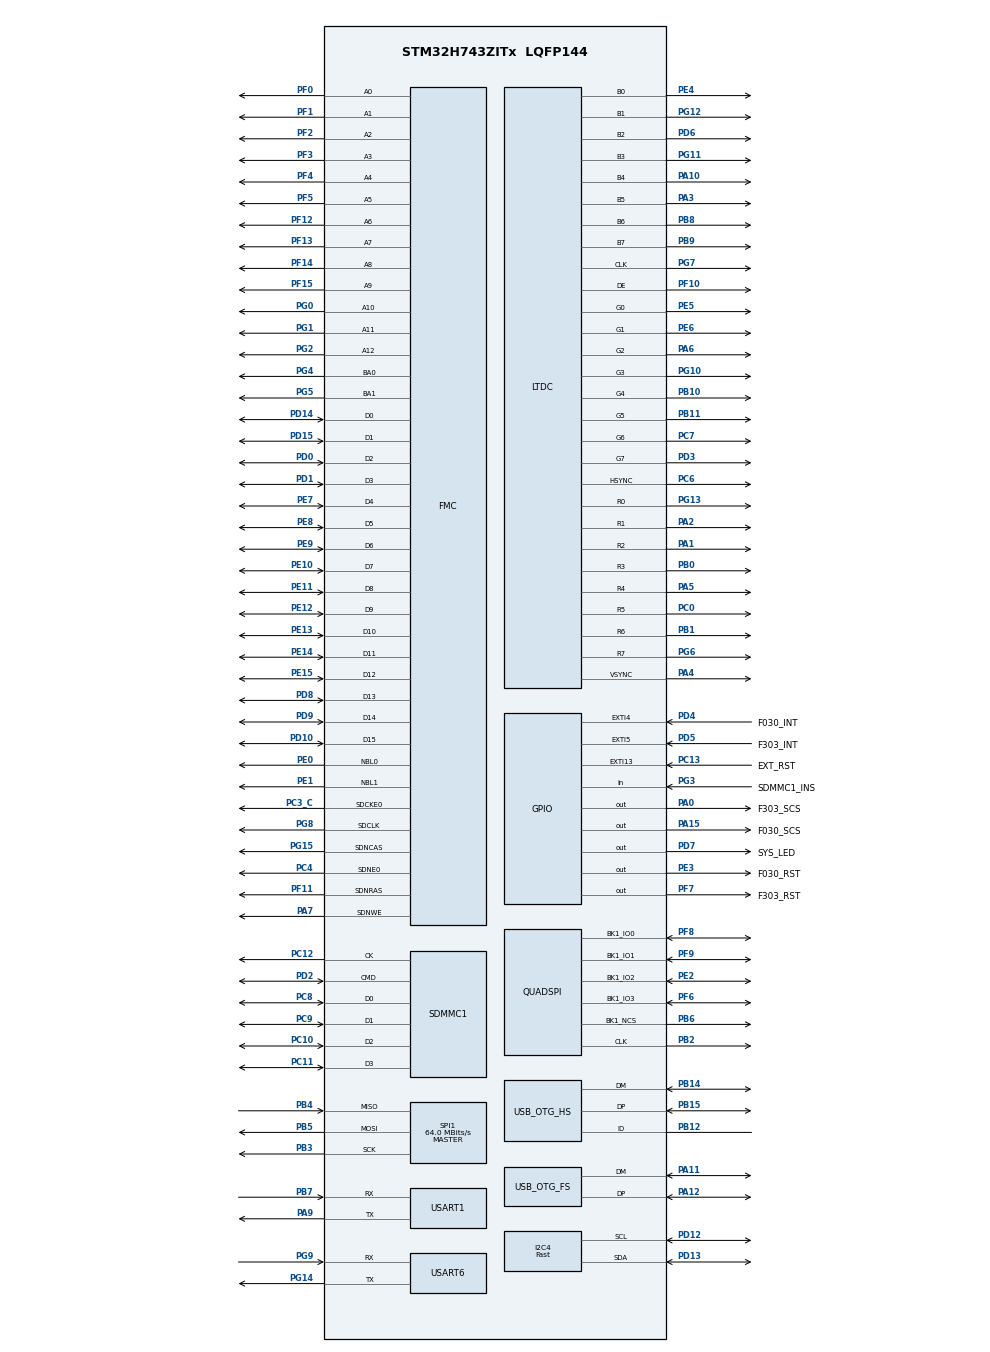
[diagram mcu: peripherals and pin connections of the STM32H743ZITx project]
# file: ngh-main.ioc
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CORTEX_M7.CPU_DCache=Enabled
CORTEX_M7.CPU_ICache=Enabled
CORTEX_M7.MPU_Control=__NULL
DMA2D.ColorMode=DMA2D_OUTPUT_ARGB8888
DMA2D.Mode=DMA2D_R2M
FATFS.BSP.number=1
FATFS.USE_DMA_CODE_SD=1
FATFS._STRF_ENCODE=3
FATFS._USE_LFN=1
FATFS0.BSP.STBoard=false
FATFS0.BSP.api=Unknown
FATFS0.BSP.i2caddr=0
FATFS0.BSP.instance=PG3
FATFS0.BSP.ip=GPIO
FATFS0.BSP.mode=Input
FATFS0.BSP.name=Detect_SDIO
FATFS0.BSP.solution=PG3
FMC.CASLatency1=FMC_SDRAM_CAS_LATENCY_2
FMC.ColumnBitsNumber1=FMC_SDRAM_COLUMN_BITS_NUM_9
FMC.ExitSelfRefreshDelay1=8
FMC.LoadToActiveDelay1=2
FMC.RCDDelay1=2
FMC.RPDelay1=2
FMC.RPDelay2=2
FMC.ReadBurst1=FMC_SDRAM_RBURST_ENABLE
FMC.ReadBurst2=FMC_SDRAM_RBURST_ENABLE
FMC.RowCycleDelay1=6
FMC.RowCycleDelay2=6
FMC.SDClockPeriod1=FMC_SDRAM_CLOCK_PERIOD_2
FMC.SDClockPeriod2=FMC_SDRAM_CLOCK_PERIOD_2
FMC.SelfRefreshTime1=6
FMC.WriteRecoveryTime1=4
I2C4.I2C_Speed_Mode=I2C_Fast
I2C4.Timing=0x009034B6
LTDC.ActiveH=480
LTDC.ActiveW=854
LTDC.Alpha0_L0=255
LTDC.Alpha_L0=255
LTDC.BlendingFactor1_L0=LTDC_BLENDING_FACTOR1_CA
LTDC.BlendingFactor2_L0=LTDC_BLENDING_FACTOR2_CA
LTDC.FBStartAdress_L0=0xC0000000
LTDC.HBP=2
LTDC.HFP=8
LTDC.HSync=2
LTDC.ImageHeight_L0=480
LTDC.ImageWidth_L0=854
LTDC.Layers=0
LTDC.PixelFormat_L0=LTDC_PIXEL_FORMAT_ARGB8888
LTDC.VBP=18
LTDC.VFP=20
LTDC.VSync=2
LTDC.WindowX1_L0=854
LTDC.WindowY1_L0=480
Mcu.Family=STM32H7
Mcu.Name=STM32H743ZITx
Mcu.Package=LQFP144
NVIC.DMA2D_IRQn=true\:2\:0\:true\:false\:true\:true
NVIC.EXTI15_10_IRQn=true\:3\:0\:true\:false\:true\:true
NVIC.LTDC_IRQn=true\:1\:0\:true\:false\:true\:true
NVIC.OTG_FS_IRQn=true\:0\:0\:false\:false\:true\:true
NVIC.PriorityGroup=NVIC_PRIORITYGROUP_4
NVIC.TIM16_IRQn=true\:0\:0\:false\:false\:true\:true
PA0.GPIO_Label=F303_SCS
PA0.GPIO_Speed=GPIO_SPEED_FREQ_VERY_HIGH
PA0.PinState=GPIO_PIN_SET
PA0.Signal=GPIO_Output
PA1.Mode=RGB888
PA1.Signal=LTDC_R2
PA10.Mode=RGB888
PA10.Signal=LTDC_B4
PA11.Mode=Device_Only
PA11.Signal=USB_OTG_FS_DM
PA12.Mode=Device_Only
PA12.Signal=USB_OTG_FS_DP
PA13\ (JTMS/SWDIO).Mode=Serial_Wire
PA13\ (JTMS/SWDIO).Signal=SYS_JTMS-SWDIO
PA14\ (JTCK/SWCLK).Mode=Serial_Wire
PA14\ (JTCK/SWCLK).Signal=SYS_JTCK-SWCLK
PA15\ (JTDI).GPIO_Label=F030_SCS
PA15\ (JTDI).GPIO_Speed=GPIO_SPEED_FREQ_VERY_HIGH
PA15\ (JTDI).PinState=GPIO_PIN_SET
PA15\ (JTDI).Signal=GPIO_Output
PA2.Mode=RGB888
PA2.Signal=LTDC_R1
PA3.Mode=RGB888
PA3.Signal=LTDC_B5
PA4.Mode=RGB888
PA4.Signal=LTDC_VSYNC
PA5.Mode=RGB888
PA5.Signal=LTDC_R4
PA6.Mode=RGB888
PA6.Signal=LTDC_G2
PA7.Signal=FMC_SDNWE
PA9.GPIO_PuPd=GPIO_PULLUP
PA9.GPIO_Speed=GPIO_SPEED_FREQ_LOW
PA9.Mode=Multiprocessor_communication
PA9.Signal=USART1_TX
PB0.Mode=RGB888
PB0.Signal=LTDC_R3
PB1.Mode=RGB888
PB1.Signal=LTDC_R6
PB10.Mode=RGB888
PB10.Signal=LTDC_G4
PB11.Mode=RGB888
PB11.Signal=LTDC_G5
PB12.Mode=OTG/Dual-Role-Device-FS
PB12.Signal=USB_OTG_HS_ID
PB14.Mode=OTG/Dual-Role-Device-FS
PB14.Signal=USB_OTG_HS_DM
PB15.Mode=OTG/Dual-Role-Device-FS
PB15.Signal=USB_OTG_HS_DP
PB2.Mode=Single Bank 1
PB2.Signal=QUADSPI_CLK
PB3\ (JTDO/TRACESWO).Mode=Full_Duplex_Master
PB3\ (JTDO/TRACESWO).Signal=SPI1_SCK
PB4\ (NJTRST).Mode=Full_Duplex_Master
PB4\ (NJTRST).Signal=SPI1_MISO
PB5.Mode=Full_Duplex_Master
PB5.Signal=SPI1_MOSI
PB6.Mode=Single Bank 1
PB6.Signal=QUADSPI_BK1_NCS
PB7.GPIO_FM7=__NULL
PB7.GPIO_PuPd=GPIO_PULLUP
PB7.GPIO_Speed=GPIO_SPEED_FREQ_LOW
PB7.Mode=Multiprocessor_communication
PB7.Signal=USART1_RX
PB8.Mode=RGB888
PB8.Signal=LTDC_B6
PB9.Mode=RGB888
PB9.Signal=LTDC_B7
PC0.Mode=RGB888
PC0.Signal=LTDC_R5
PC10.Mode=SD_4_bits_Wide_bus
PC10.Signal=SDMMC1_D2
PC11.Mode=SD_4_bits_Wide_bus
PC11.Signal=SDMMC1_D3
PC12.Mode=SD_4_bits_Wide_bus
PC12.Signal=SDMMC1_CK
PC13.GPIO_Label=EXT_RST
PC13.GPIO_ModeDefaultEXTI=GPIO_MODE_IT_RISING_FALLING
PC13.GPIO_PuPd=GPIO_PULLUP
PC13.Signal=GPXTI13
PC14-OSC32_IN\ (OSC32_IN).Mode=LSE-External-Oscillator
PC14-OSC32_IN\ (OSC32_IN).Signal=RCC_OSC32_IN
PC15-OSC32_OUT\ (OSC32_OUT).Mode=LSE-External-Oscillator
PC15-OSC32_OUT\ (OSC32_OUT).Signal=RCC_OSC32_OUT
PC3_C.Mode=SdramChipSelect1_1
PC3_C.Signal=FMC_SDCKE0
PC4.Mode=SdramChipSelect1_1
PC4.Signal=FMC_SDNE0
PC6.Mode=RGB888
PC6.Signal=LTDC_HSYNC
PC7.Mode=RGB888
PC7.Signal=LTDC_G6
PC8.Mode=SD_4_bits_Wide_bus
PC8.Signal=SDMMC1_D0
PC9.Mode=SD_4_bits_Wide_bus
PC9.Signal=SDMMC1_D1
PD0.Signal=FMC_D2_DA2
PD1.Signal=FMC_D3_DA3
PD10.Signal=FMC_D15_DA15
PD12.Mode=I2C
PD12.Signal=I2C4_SCL
PD13.Mode=I2C
PD13.Signal=I2C4_SDA
PD14.Signal=FMC_D0_DA0
PD15.Signal=FMC_D1_DA1
PD2.Mode=SD_4_bits_Wide_bus
PD2.Signal=SDMMC1_CMD
PD3.Mode=RGB888
PD3.Signal=LTDC_G7
PD4.GPIO_Label=F030_INT
PD4.Signal=GPXTI4
PD5.GPIO_Label=F303_INT
PD5.Signal=GPXTI5
PD6.Mode=RGB888
PD6.Signal=LTDC_B2
PD7.GPIO_Label=SYS_LED
PD7.GPIO_Speed=GPIO_SPEED_FREQ_VERY_HIGH
PD7.Signal=GPIO_Output
PD8.Signal=FMC_D13_DA13
PD9.Signal=FMC_D14_DA14
PE0.Signal=FMC_NBL0
PE1.Signal=FMC_NBL1
PE10.Signal=FMC_D7_DA7
PE11.Signal=FMC_D8_DA8
PE12.Signal=FMC_D9_DA9
PE13.Signal=FMC_D10_DA10
PE14.Signal=FMC_D11_DA11
PE15.Signal=FMC_D12_DA12
PE2.Mode=Single Bank 1
PE2.Signal=QUADSPI_BK1_IO2
PE3.GPIO_Label=F030_RST
PE3.GPIO_Speed=GPIO_SPEED_FREQ_VERY_HIGH
PE3.PinState=GPIO_PIN_SET
PE3.Signal=GPIO_Output
PE4.Mode=RGB888
PE4.Signal=LTDC_B0
PE5.Mode=RGB888
PE5.Signal=LTDC_G0
PE6.Mode=RGB888
PE6.Signal=LTDC_G1
PE7.Signal=FMC_D4_DA4
PE8.Signal=FMC_D5_DA5
PE9.Signal=FMC_D6_DA6
PF0.Signal=FMC_A0
PF1.Signal=FMC_A1
PF10.Mode=RGB888
PF10.Signal=LTDC_DE
PF11.Signal=FMC_SDNRAS
PF12.Signal=FMC_A6
PF13.Signal=FMC_A7
PF14.Signal=FMC_A8
PF15.Signal=FMC_A9
PF2.Signal=FMC_A2
PF3.Signal=FMC_A3
PF4.Signal=FMC_A4
PF5.Signal=FMC_A5
PF6.Mode=Single Bank 1
PF6.Signal=QUADSPI_BK1_IO3
PF7.GPIO_Label=F303_RST
PF7.GPIO_Speed=GPIO_SPEED_FREQ_VERY_HIGH
PF7.PinState=GPIO_PIN_SET
PF7.Signal=GPIO_Output
PF8.Mode=Single Bank 1
PF8.Signal=QUADSPI_BK1_IO0
PF9.Mode=Single Bank 1
PF9.Signal=QUADSPI_BK1_IO1
PG0.Signal=FMC_A10
PG1.Signal=FMC_A11
PG10.Mode=RGB888
PG10.Signal=LTDC_G3
PG11.Mode=RGB888
PG11.Signal=LTDC_B3
PG12.Mode=RGB888
PG12.Signal=LTDC_B1
PG13.Mode=RGB888
PG13.Signal=LTDC_R0
PG14.Mode=Asynchronous
PG14.Signal=USART6_TX
PG15.Signal=FMC_SDNCAS
PG2.Signal=FMC_A12
PG3.GPIO_Label=SDMMC1_INS
PG3.GPIO_PuPd=GPIO_PULLUP
PG3.Signal=GPIO_Input
PG4.Signal=FMC_A14_BA0
PG5.Signal=FMC_A15_BA1
PG6.Mode=RGB888
PG6.Signal=LTDC_R7
PG7.Mode=RGB888
PG7.Signal=LTDC_CLK
PG8.Signal=FMC_SDCLK
PG9.Mode=Asynchronous
PG9.Signal=USART6_RX
PH0-OSC_IN\ (PH0).Mode=HSE-External-Oscillator
PH0-OSC_IN\ (PH0).Signal=RCC_OSC_IN
PH1-OSC_OUT\ (PH1).Mode=HSE-External-Oscillator
PH1-OSC_OUT\ (PH1).Signal=RCC_OSC_OUT
ProjectManager.HeapSize=0x200
ProjectManager.StackSize=0x400
ProjectManager.TargetToolchain=SW4STM32
QUADSPI.ChipSelectHighTime=QSPI_CS_HIGH_TIME_2_CYCLE
QUADSPI.ClockPrescaler=1
QUADSPI.FifoThreshold=4
QUADSPI.FlashSize=22
QUADSPI.SampleShifting=QSPI_SAMPLE_SHIFTING_HALFCYCLE
RCC.ADCFreq_Value=128000000
RCC.APB1Freq_Value=100000000
RCC.APB2Freq_Value=100000000
RCC.APB3Freq_Value=100000000
RCC.APB4Freq_Value=100000000
RCC.CKPERSourceSelection=RCC_CLKPSOURCE_CSI
RCC.CortexFreq_Value=400000000
RCC.D1PPRE=RCC_APB3_DIV2
RCC.D2PPRE1=RCC_APB1_DIV2
RCC.D2PPRE2=RCC_APB2_DIV2
RCC.D3PPRE=RCC_APB4_DIV2
RCC.DIVM1=4
RCC.DIVM2=4
RCC.DIVM3=4
RCC.DIVN1=400
RCC.DIVN2=128
RCC.DIVN3=96
RCC.DIVQ1=8
RCC.DIVQ3=4
RCC.DIVR3=6
RCC.HCLKFreq_Value=200000000
RCC.HPRE=RCC_HCLK_DIV2
RCC.HSE_VALUE=8000000
RCC.PLL1_VCI_Range-AdvancedSettings=RCC_PLL1VCIRANGE_0
RCC.RCC_MCO1Source=RCC_MCO1SOURCE_PLL1QCLK
RCC.RCC_MCODiv1=RCC_MCODIV_10
RCC.RNGCLockSelection=RCC_RNGCLKSOURCE_PLL
RCC.RTCClockSelection=RCC_RTCCLKSOURCE_LSE
RCC.SDMMC1CLockSelection=RCC_SDMMCCLKSOURCE_PLL2
RCC.SPI123CLockSelection=RCC_SPI123CLKSOURCE_PLL2
RCC.SYSCLKFreq_VALUE=400000000
RCC.SYSCLKSource=RCC_SYSCLKSOURCE_PLLCLK
RCC.USART16CLockSelection=RCC_USART16CLKSOURCE_PLL2
RCC.USBCLockSelection=RCC_USBCLKSOURCE_PLL3
RCC.USBFreq_Value=48000000
SDMMC1.ClockDiv=4
SH.FMC_A0.0=FMC_A0,13b-sda1
SH.FMC_A1.0=FMC_A1,13b-sda1
SH.FMC_A10.0=FMC_A10,13b-sda1
SH.FMC_A11.0=FMC_A11,13b-sda1
SH.FMC_A12.0=FMC_A12,13b-sda1
SH.FMC_A14_BA0.0=FMC_BA0,FourSdramBanks1
SH.FMC_A15_BA1.0=FMC_BA1,FourSdramBanks1
SH.FMC_A2.0=FMC_A2,13b-sda1
SH.FMC_A3.0=FMC_A3,13b-sda1
SH.FMC_A4.0=FMC_A4,13b-sda1
SH.FMC_A5.0=FMC_A5,13b-sda1
SH.FMC_A6.0=FMC_A6,13b-sda1
SH.FMC_A7.0=FMC_A7,13b-sda1
SH.FMC_A8.0=FMC_A8,13b-sda1
SH.FMC_A9.0=FMC_A9,13b-sda1
SH.FMC_D0_DA0.0=FMC_D0,sd-16b-d1
SH.FMC_D10_DA10.0=FMC_D10,sd-16b-d1
SH.FMC_D11_DA11.0=FMC_D11,sd-16b-d1
SH.FMC_D12_DA12.0=FMC_D12,sd-16b-d1
SH.FMC_D13_DA13.0=FMC_D13,sd-16b-d1
SH.FMC_D14_DA14.0=FMC_D14,sd-16b-d1
SH.FMC_D15_DA15.0=FMC_D15,sd-16b-d1
SH.FMC_D1_DA1.0=FMC_D1,sd-16b-d1
SH.FMC_D2_DA2.0=FMC_D2,sd-16b-d1
SH.FMC_D3_DA3.0=FMC_D3,sd-16b-d1
SH.FMC_D4_DA4.0=FMC_D4,sd-16b-d1
SH.FMC_D5_DA5.0=FMC_D5,sd-16b-d1
SH.FMC_D6_DA6.0=FMC_D6,sd-16b-d1
SH.FMC_D7_DA7.0=FMC_D7,sd-16b-d1
SH.FMC_D8_DA8.0=FMC_D8,sd-16b-d1
SH.FMC_D9_DA9.0=FMC_D9,sd-16b-d1
SH.FMC_NBL0.0=FMC_NBL0,Sd2ByteEnable1
SH.FMC_NBL1.0=FMC_NBL1,Sd2ByteEnable1
SH.FMC_SDCLK.0=FMC_SDCLK,13b-sda1
SH.FMC_SDNCAS.0=FMC_SDNCAS,13b-sda1
SH.FMC_SDNRAS.0=FMC_SDNRAS,13b-sda1
SH.FMC_SDNWE.0=FMC_SDNWE,13b-sda1
SPI1.BaudRatePrescaler=SPI_BAUDRATEPRESCALER_2
SPI1.CalculateBaudRate=64.0 MBits/s
SPI1.DataSize=SPI_DATASIZE_8BIT
SPI1.Direction=SPI_DIRECTION_2LINES
SPI1.Mode=SPI_MODE_MASTER
SPI1.VirtualType=VM_MASTER
TIM16.Period=99
TIM16.Prescaler=200
USART1.VirtualMode-Multiprocessor_communication=VM_ASYNC
USART6.VirtualMode-Asynchronous=VM_ASYNC
USB_DEVICE.CLASS_NAME_FS=MSC
USB_DEVICE.CONFIGURATION_STRING_MSC_FS=NGH Config
USB_DEVICE.INTERFACE_STRING_MSC_FS=NGH Interface
USB_DEVICE.MANUFACTURER_STRING-MSC_FS=NSDN
USB_DEVICE.PRODUCT_STRING_MSC_FS=NyaGame Hydro v1.0
USB_DEVICE.VirtualMode-MSC_FS=Msc
USB_DEVICE.VirtualModeFS=Msc_FS
USB_OTG_FS.VirtualMode=Device_Only
VP_DMA2D_VS_DMA2D.Mode=DMA2D_Activate
VP_FATFS_VS_SDIO.Mode=SDIO
VP_RNG_VS_RNG.Mode=RNG_Activate
VP_RTC_VS_RTC_Activate.Mode=RTC_Enabled
VP_TIM16_VS_ClockSourceINT.Mode=Enable_Timer
VP_USB_DEVICE_VS_USB_DEVICE_MSC_FS.Mode=MSC_FS
board=custom

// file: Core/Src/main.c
/* USER CODE BEGIN Header */
/**
  ******************************************************************************
  * @file           : main.c
  * @brief          : Main program body
  ******************************************************************************
  * This notice applies to any and all portions of this file
  * that are not between comment pairs USER CODE BEGIN and
  * USER CODE END. Other portions of this file, whether
  * inserted by the user or by software development tools
  * are owned by their respective copyright owners.
  *
  * Copyright (c) 2018 STMicroelectronics International N.V.
  * All rights reserved.
  *
  * Redistribution and use in source and binary forms, with or without
  * modification, are permitted, provided that the following conditions are met:
  *
  * 1. Redistribution of source code must retain the above copyright notice,
  *    this list of conditions and the following disclaimer.
  * 2. Redistributions in binary form must reproduce the above copyright notice,
  *    this list of conditions and the following disclaimer in the documentation
  *    and/or other materials provided with the distribution.
  * 3. Neither the name of STMicroelectronics nor the names of other
  *    contributors to this software may be used to endorse or promote products
  *    derived from this software without specific written permission.
  * 4. This software, including modifications and/or derivative works of this
  *    software, must execute solely and exclusively on microcontroller or
  *    microprocessor devices manufactured by or for STMicroelectronics.
  * 5. Redistribution and use of this software other than as permitted under
  *    this license is void and will automatically terminate your rights under
  *    this license.
  *
  * THIS SOFTWARE IS PROVIDED BY STMICROELECTRONICS AND CONTRIBUTORS "AS IS"
  * AND ANY EXPRESS, IMPLIED OR STATUTORY WARRANTIES, INCLUDING, BUT NOT
  * LIMITED TO, THE IMPLIED WARRANTIES OF MERCHANTABILITY, FITNESS FOR A
  * PARTICULAR PURPOSE AND NON-INFRINGEMENT OF THIRD PARTY INTELLECTUAL PROPERTY
  * RIGHTS ARE DISCLAIMED TO THE FULLEST EXTENT PERMITTED BY LAW. IN NO EVENT
  * SHALL STMICROELECTRONICS OR CONTRIBUTORS BE LIABLE FOR ANY DIRECT, INDIRECT,
  * INCIDENTAL, SPECIAL, EXEMPLARY, OR CONSEQUENTIAL DAMAGES (INCLUDING, BUT NOT
  * LIMITED TO, PROCUREMENT OF SUBSTITUTE GOODS OR SERVICES; LOSS OF USE, DATA,
  * OR PROFITS; OR BUSINESS INTERRUPTION) HOWEVER CAUSED AND ON ANY THEORY OF
  * LIABILITY, WHETHER IN CONTRACT, STRICT LIABILITY, OR TORT (INCLUDING
  * NEGLIGENCE OR OTHERWISE) ARISING IN ANY WAY OUT OF THE USE OF THIS SOFTWARE,
  * EVEN IF ADVISED OF THE POSSIBILITY OF SUCH DAMAGE.
  *
  ******************************************************************************
  */
/* USER CODE END Header */

#include "main.h"
#include "fatfs.h"
#include "usb_device.h"

/* USER CODE BEGIN Includes */
#include <string.h>
#include <stdio.h>
#include "dram.h"

#include "ngh_bios.h"
/* USER CODE END Includes */

DMA2D_HandleTypeDef hdma2d;

I2C_HandleTypeDef hi2c4;

LTDC_HandleTypeDef hltdc;

QSPI_HandleTypeDef hqspi;

RNG_HandleTypeDef hrng;

RTC_HandleTypeDef hrtc;

SD_HandleTypeDef hsd1;

SPI_HandleTypeDef hspi1;

TIM_HandleTypeDef htim16;

UART_HandleTypeDef huart1;
UART_HandleTypeDef huart6;

SDRAM_HandleTypeDef hsdram1;

/* USER CODE BEGIN PV */
__IO uint8_t dma2dXferCpltFlag = 0;
/* USER CODE END PV */

void SystemClock_Config(void);
static void MX_GPIO_Init(void);
static void MX_LTDC_Init(void);
static void MX_SDMMC1_SD_Init(void);
static void MX_QUADSPI_Init(void);
static void MX_FMC_Init(void);
static void MX_I2C4_Init(void);
static void MX_SPI1_Init(void);
static void MX_USART1_UART_Init(void);
static void MX_USART6_UART_Init(void);
static void MX_USB_OTG_HS_USB_Init(void);
static void MX_DMA2D_Init(void);
static void MX_RNG_Init(void);
static void MX_RTC_Init(void);
static void MX_TIM16_Init(void);

/* USER CODE BEGIN 0 */
void HAL_GPIO_EXTI_Callback(uint16_t GPIO_Pin) {
	if (GPIO_Pin == GPIO_PIN_13) {
		GPIO_PinState state = HAL_GPIO_ReadPin(EXT_RST_GPIO_Port, EXT_RST_Pin);
		HAL_GPIO_WritePin(F030_RST_GPIO_Port, F030_RST_Pin, state);
		HAL_GPIO_WritePin(F303_RST_GPIO_Port, F303_RST_Pin, state);
	}
}

__IO uint32_t _cnt = 0, _max = 5000;
void HAL_TIM_PeriodElapsedCallback(TIM_HandleTypeDef *htim) {
	if (htim == &htim16) {
		if (_cnt < _max) _cnt += 1;
		else {
			_cnt = 0;
			HAL_GPIO_TogglePin(SYS_LED_GPIO_Port, SYS_LED_Pin);
		}
	}
}

static void XferCpltCallback(DMA2D_HandleTypeDef *hdma2d) {
  dma2dXferCpltFlag = 1;
}

void fillByDMA2D(uint32_t color, uint32_t w, uint32_t h) {
  dma2dXferCpltFlag = 0;
  HAL_DMA2D_Start_IT(&hdma2d, color, 0xC0000000, w, h);
  while (dma2dXferCpltFlag == 0);
}
/* USER CODE END 0 */

int main(void)
{
  /* USER CODE BEGIN 1 */
  dma2dXferCpltFlag = 0;
  /* USER CODE END 1 */

  /* Enable I-Cache---------------------------------------------------------*/
  SCB_EnableICache();

  /* Enable D-Cache---------------------------------------------------------*/
  SCB_EnableDCache();

  /* MCU Configuration--------------------------------------------------------*/

  /* Reset of all peripherals, Initializes the Flash interface and the Systick. */
  HAL_Init();

  /* Configure the system clock */
  SystemClock_Config();

  /* Initialize all configured peripherals */
  MX_GPIO_Init();
  MX_LTDC_Init();
  MX_SDMMC1_SD_Init();
  MX_QUADSPI_Init();
  MX_FMC_Init();
  MX_I2C4_Init();
  MX_SPI1_Init();
  MX_USART1_UART_Init();
  MX_USART6_UART_Init();
  MX_USB_OTG_HS_USB_Init();
  MX_DMA2D_Init();
  MX_RNG_Init();
  MX_RTC_Init();
  MX_FATFS_Init();
  MX_USB_DEVICE_Init();
  MX_TIM16_Init();
  /* USER CODE BEGIN 2 */
  SDRAM_Init(&hsdram1);
  HAL_TIM_Base_Start_IT(&htim16);

  HAL_GPIO_WritePin(F030_RST_GPIO_Port, F030_RST_Pin, GPIO_PIN_RESET);
  HAL_Delay(50);
  HAL_GPIO_WritePin(F030_RST_GPIO_Port, F030_RST_Pin, GPIO_PIN_SET);

  HAL_GPIO_WritePin(F303_RST_GPIO_Port, F303_RST_Pin, GPIO_PIN_RESET);
  HAL_Delay(50);
  HAL_GPIO_WritePin(F303_RST_GPIO_Port, F303_RST_Pin, GPIO_PIN_SET);

  HAL_Delay(500);

  fillByDMA2D(0xFFFFFF, 854, 480);
  HAL_Delay(500);

  ngh_setup();
  /* USER CODE END 2 */

  /* Infinite loop */
  /* USER CODE BEGIN WHILE */
  while (1) ngh_loop();
    /* USER CODE END WHILE */

}

void SystemClock_Config(void)
{
  RCC_OscInitTypeDef RCC_OscInitStruct = {0};
  RCC_ClkInitTypeDef RCC_ClkInitStruct = {0};
  RCC_PeriphCLKInitTypeDef PeriphClkInitStruct = {0};

  /**Supply configuration update enable
  */
  MODIFY_REG(PWR->CR3, PWR_CR3_SCUEN, 0);
  /**Configure the main internal regulator output voltage
  */
  __HAL_PWR_VOLTAGESCALING_CONFIG(PWR_REGULATOR_VOLTAGE_SCALE1);

  while ((PWR->D3CR & (PWR_D3CR_VOSRDY)) != PWR_D3CR_VOSRDY)
  {

  }
  /**Configure LSE Drive Capability
  */
  HAL_PWR_EnableBkUpAccess();
  __HAL_RCC_LSEDRIVE_CONFIG(RCC_LSEDRIVE_LOW);
  /**Macro to configure the PLL clock source
  */
  __HAL_RCC_PLL_PLLSOURCE_CONFIG(RCC_PLLSOURCE_HSE);
  /**Initializes the CPU, AHB and APB busses clocks
  */
  RCC_OscInitStruct.OscillatorType = RCC_OSCILLATORTYPE_HSE|RCC_OSCILLATORTYPE_LSE;
  RCC_OscInitStruct.HSEState = RCC_HSE_ON;
  RCC_OscInitStruct.LSEState = RCC_LSE_ON;
  RCC_OscInitStruct.PLL.PLLState = RCC_PLL_ON;
  RCC_OscInitStruct.PLL.PLLSource = RCC_PLLSOURCE_HSE;
  RCC_OscInitStruct.PLL.PLLM = 4;
  RCC_OscInitStruct.PLL.PLLN = 400;
  RCC_OscInitStruct.PLL.PLLP = 2;
  RCC_OscInitStruct.PLL.PLLQ = 8;
  RCC_OscInitStruct.PLL.PLLR = 2;
  RCC_OscInitStruct.PLL.PLLRGE = RCC_PLL1VCIRANGE_1;
  RCC_OscInitStruct.PLL.PLLVCOSEL = RCC_PLL1VCOWIDE;
  RCC_OscInitStruct.PLL.PLLFRACN = 0;
  if (HAL_RCC_OscConfig(&RCC_OscInitStruct) != HAL_OK)
  {
    Error_Handler();
  }
  /**Initializes the CPU, AHB and APB busses clocks
  */
  RCC_ClkInitStruct.ClockType = RCC_CLOCKTYPE_HCLK|RCC_CLOCKTYPE_SYSCLK
                              |RCC_CLOCKTYPE_PCLK1|RCC_CLOCKTYPE_PCLK2
                              |RCC_CLOCKTYPE_D3PCLK1|RCC_CLOCKTYPE_D1PCLK1;
  RCC_ClkInitStruct.SYSCLKSource = RCC_SYSCLKSOURCE_PLLCLK;
  RCC_ClkInitStruct.SYSCLKDivider = RCC_SYSCLK_DIV1;
  RCC_ClkInitStruct.AHBCLKDivider = RCC_HCLK_DIV2;
  RCC_ClkInitStruct.APB3CLKDivider = RCC_APB3_DIV2;
  RCC_ClkInitStruct.APB1CLKDivider = RCC_APB1_DIV2;
  RCC_ClkInitStruct.APB2CLKDivider = RCC_APB2_DIV2;
  RCC_ClkInitStruct.APB4CLKDivider = RCC_APB4_DIV2;

  if (HAL_RCC_ClockConfig(&RCC_ClkInitStruct, FLASH_LATENCY_2) != HAL_OK)
  {
    Error_Handler();
  }
  PeriphClkInitStruct.PeriphClockSelection = RCC_PERIPHCLK_RTC|RCC_PERIPHCLK_LTDC
                              |RCC_PERIPHCLK_USART6|RCC_PERIPHCLK_USART1
                              |RCC_PERIPHCLK_RNG|RCC_PERIPHCLK_SPI1
                              |RCC_PERIPHCLK_SDMMC|RCC_PERIPHCLK_I2C4
                              |RCC_PERIPHCLK_USB|RCC_PERIPHCLK_QSPI
                              |RCC_PERIPHCLK_FMC;
  PeriphClkInitStruct.PLL2.PLL2M = 4;
  PeriphClkInitStruct.PLL2.PLL2N = 128;
  PeriphClkInitStruct.PLL2.PLL2P = 2;
  PeriphClkInitStruct.PLL2.PLL2Q = 2;
  PeriphClkInitStruct.PLL2.PLL2R = 2;
  PeriphClkInitStruct.PLL2.PLL2RGE = RCC_PLL2VCIRANGE_1;
  PeriphClkInitStruct.PLL2.PLL2VCOSEL = RCC_PLL2VCOWIDE;
  PeriphClkInitStruct.PLL2.PLL2FRACN = 0;
  PeriphClkInitStruct.PLL3.PLL3M = 4;
  PeriphClkInitStruct.PLL3.PLL3N = 96;
  PeriphClkInitStruct.PLL3.PLL3P = 2;
  PeriphClkInitStruct.PLL3.PLL3Q = 4;
  PeriphClkInitStruct.PLL3.PLL3R = 6;
  PeriphClkInitStruct.PLL3.PLL3RGE = RCC_PLL3VCIRANGE_1;
  PeriphClkInitStruct.PLL3.PLL3VCOSEL = RCC_PLL3VCOWIDE;
  PeriphClkInitStruct.PLL3.PLL3FRACN = 0;
  PeriphClkInitStruct.FmcClockSelection = RCC_FMCCLKSOURCE_D1HCLK;
  PeriphClkInitStruct.QspiClockSelection = RCC_QSPICLKSOURCE_D1HCLK;
  PeriphClkInitStruct.SdmmcClockSelection = RCC_SDMMCCLKSOURCE_PLL2;
  PeriphClkInitStruct.Spi123ClockSelection = RCC_SPI123CLKSOURCE_PLL2;
  PeriphClkInitStruct.Usart16ClockSelection = RCC_USART16CLKSOURCE_PLL2;
  PeriphClkInitStruct.RngClockSelection = RCC_RNGCLKSOURCE_PLL;
  PeriphClkInitStruct.UsbClockSelection = RCC_USBCLKSOURCE_PLL3;
  PeriphClkInitStruct.I2c4ClockSelection = RCC_I2C4CLKSOURCE_D3PCLK1;
  PeriphClkInitStruct.RTCClockSelection = RCC_RTCCLKSOURCE_LSE;
  if (HAL_RCCEx_PeriphCLKConfig(&PeriphClkInitStruct) != HAL_OK)
  {
    Error_Handler();
  }
}

static void MX_DMA2D_Init(void)
{

  /* USER CODE BEGIN DMA2D_Init 1 */
  hdma2d.XferCpltCallback = XferCpltCallback;
  /* USER CODE END DMA2D_Init 1 */
  hdma2d.Instance = DMA2D;
  hdma2d.Init.Mode = DMA2D_R2M;
  hdma2d.Init.ColorMode = DMA2D_OUTPUT_ARGB8888;
  hdma2d.Init.OutputOffset = 0;
  if (HAL_DMA2D_Init(&hdma2d) != HAL_OK)
  {
    Error_Handler();
  }

}

static void MX_I2C4_Init(void)
{

  hi2c4.Instance = I2C4;
  hi2c4.Init.Timing = 0x009034B6;
  hi2c4.Init.OwnAddress1 = 0;
  hi2c4.Init.AddressingMode = I2C_ADDRESSINGMODE_7BIT;
  hi2c4.Init.DualAddressMode = I2C_DUALADDRESS_DISABLE;
  hi2c4.Init.OwnAddress2 = 0;
  hi2c4.Init.OwnAddress2Masks = I2C_OA2_NOMASK;
  hi2c4.Init.GeneralCallMode = I2C_GENERALCALL_DISABLE;
  hi2c4.Init.NoStretchMode = I2C_NOSTRETCH_DISABLE;
  if (HAL_I2C_Init(&hi2c4) != HAL_OK)
  {
    Error_Handler();
  }
  /**Configure Analogue filter
  */
  if (HAL_I2CEx_ConfigAnalogFilter(&hi2c4, I2C_ANALOGFILTER_ENABLE) != HAL_OK)
  {
    Error_Handler();
  }
  /**Configure Digital filter
  */
  if (HAL_I2CEx_ConfigDigitalFilter(&hi2c4, 0) != HAL_OK)
  {
    Error_Handler();
  }

}

static void MX_LTDC_Init(void)
{

  LTDC_LayerCfgTypeDef pLayerCfg = {0};

  hltdc.Instance = LTDC;
  hltdc.Init.HSPolarity = LTDC_HSPOLARITY_AL;
  hltdc.Init.VSPolarity = LTDC_VSPOLARITY_AL;
  hltdc.Init.DEPolarity = LTDC_DEPOLARITY_AL;
  hltdc.Init.PCPolarity = LTDC_PCPOLARITY_IPC;
  hltdc.Init.HorizontalSync = 1;
  hltdc.Init.VerticalSync = 1;
  hltdc.Init.AccumulatedHBP = 3;
  hltdc.Init.AccumulatedVBP = 19;
  hltdc.Init.AccumulatedActiveW = 857;
  hltdc.Init.AccumulatedActiveH = 499;
  hltdc.Init.TotalWidth = 865;
  hltdc.Init.TotalHeigh = 519;
  hltdc.Init.Backcolor.Blue = 0;
  hltdc.Init.Backcolor.Green = 0;
  hltdc.Init.Backcolor.Red = 0;
  if (HAL_LTDC_Init(&hltdc) != HAL_OK)
  {
    Error_Handler();
  }
  pLayerCfg.WindowX0 = 0;
  pLayerCfg.WindowX1 = 854;
  pLayerCfg.WindowY0 = 0;
  pLayerCfg.WindowY1 = 480;
  pLayerCfg.PixelFormat = LTDC_PIXEL_FORMAT_ARGB8888;
  pLayerCfg.Alpha = 255;
  pLayerCfg.Alpha0 = 255;
  pLayerCfg.BlendingFactor1 = LTDC_BLENDING_FACTOR1_CA;
  pLayerCfg.BlendingFactor2 = LTDC_BLENDING_FACTOR2_CA;
  pLayerCfg.FBStartAdress = 0xC0000000;
  pLayerCfg.ImageWidth = 854;
  pLayerCfg.ImageHeight = 480;
  pLayerCfg.Backcolor.Blue = 0;
  pLayerCfg.Backcolor.Green = 0;
  pLayerCfg.Backcolor.Red = 0;
  if (HAL_LTDC_ConfigLayer(&hltdc, &pLayerCfg, 0) != HAL_OK)
  {
    Error_Handler();
  }

}

static void MX_QUADSPI_Init(void)
{

  /* QUADSPI parameter configuration*/
  hqspi.Instance = QUADSPI;
  hqspi.Init.ClockPrescaler = 1;
  hqspi.Init.FifoThreshold = 4;
  hqspi.Init.SampleShifting = QSPI_SAMPLE_SHIFTING_HALFCYCLE;
  hqspi.Init.FlashSize = 22;
  hqspi.Init.ChipSelectHighTime = QSPI_CS_HIGH_TIME_2_CYCLE;
  hqspi.Init.ClockMode = QSPI_CLOCK_MODE_0;
  hqspi.Init.FlashID = QSPI_FLASH_ID_1;
  hqspi.Init.DualFlash = QSPI_DUALFLASH_DISABLE;
  if (HAL_QSPI_Init(&hqspi) != HAL_OK)
  {
    Error_Handler();
  }

}

static void MX_RNG_Init(void)
{

  hrng.Instance = RNG;
  hrng.Init.ClockErrorDetection = RNG_CED_ENABLE;
  if (HAL_RNG_Init(&hrng) != HAL_OK)
  {
    Error_Handler();
  }

}

static void MX_RTC_Init(void)
{

  /**Initialize RTC Only
  */
  hrtc.Instance = RTC;
  hrtc.Init.HourFormat = RTC_HOURFORMAT_24;
  hrtc.Init.AsynchPrediv = 127;
  hrtc.Init.SynchPrediv = 255;
  hrtc.Init.OutPut = RTC_OUTPUT_DISABLE;
  hrtc.Init.OutPutPolarity = RTC_OUTPUT_POLARITY_HIGH;
  hrtc.Init.OutPutType = RTC_OUTPUT_TYPE_OPENDRAIN;
  hrtc.Init.OutPutRemap = RTC_OUTPUT_REMAP_NONE;
  if (HAL_RTC_Init(&hrtc) != HAL_OK)
  {
    Error_Handler();
  }

}

static void MX_SDMMC1_SD_Init(void)
{

  hsd1.Instance = SDMMC1;
  hsd1.Init.ClockEdge = SDMMC_CLOCK_EDGE_RISING;
  hsd1.Init.ClockPowerSave = SDMMC_CLOCK_POWER_SAVE_DISABLE;
  hsd1.Init.BusWide = SDMMC_BUS_WIDE_4B;
  hsd1.Init.HardwareFlowControl = SDMMC_HARDWARE_FLOW_CONTROL_DISABLE;
  hsd1.Init.ClockDiv = 4;

}

static void MX_SPI1_Init(void)
{

  /* SPI1 parameter configuration*/
  hspi1.Instance = SPI1;
  hspi1.Init.Mode = SPI_MODE_MASTER;
  hspi1.Init.Direction = SPI_DIRECTION_2LINES;
  hspi1.Init.DataSize = SPI_DATASIZE_8BIT;
  hspi1.Init.CLKPolarity = SPI_POLARITY_LOW;
  hspi1.Init.CLKPhase = SPI_PHASE_1EDGE;
  hspi1.Init.NSS = SPI_NSS_SOFT;
  hspi1.Init.BaudRatePrescaler = SPI_BAUDRATEPRESCALER_2;
  hspi1.Init.FirstBit = SPI_FIRSTBIT_MSB;
  hspi1.Init.TIMode = SPI_TIMODE_DISABLE;
  hspi1.Init.CRCCalculation = SPI_CRCCALCULATION_DISABLE;
  hspi1.Init.CRCPolynomial = 7;
  hspi1.Init.NSSPMode = SPI_NSS_PULSE_ENABLE;
  hspi1.Init.NSSPolarity = SPI_NSS_POLARITY_LOW;
  hspi1.Init.FifoThreshold = SPI_FIFO_THRESHOLD_01DATA;
  hspi1.Init.TxCRCInitializationPattern = SPI_CRC_INITIALIZATION_ALL_ZERO_PATTERN;
  hspi1.Init.RxCRCInitializationPattern = SPI_CRC_INITIALIZATION_ALL_ZERO_PATTERN;
  hspi1.Init.MasterSSIdleness = SPI_MASTER_SS_IDLENESS_00CYCLE;
  hspi1.Init.MasterInterDataIdleness = SPI_MASTER_INTERDATA_IDLENESS_00CYCLE;
  hspi1.Init.MasterReceiverAutoSusp = SPI_MASTER_RX_AUTOSUSP_DISABLE;
  hspi1.Init.MasterKeepIOState = SPI_MASTER_KEEP_IO_STATE_DISABLE;
  hspi1.Init.IOSwap = SPI_IO_SWAP_DISABLE;
  if (HAL_SPI_Init(&hspi1) != HAL_OK)
  {
    Error_Handler();
  }

}

static void MX_TIM16_Init(void)
{

  htim16.Instance = TIM16;
  htim16.Init.Prescaler = 200;
  htim16.Init.CounterMode = TIM_COUNTERMODE_UP;
  htim16.Init.Period = 99;
  htim16.Init.ClockDivision = TIM_CLOCKDIVISION_DIV1;
  htim16.Init.RepetitionCounter = 0;
  htim16.Init.AutoReloadPreload = TIM_AUTORELOAD_PRELOAD_DISABLE;
  if (HAL_TIM_Base_Init(&htim16) != HAL_OK)
  {
    Error_Handler();
  }

}

static void MX_USART1_UART_Init(void)
{

  huart1.Instance = USART1;
  huart1.Init.BaudRate = 115200;
  huart1.Init.WordLength = UART_WORDLENGTH_8B;
  huart1.Init.StopBits = UART_STOPBITS_1;
  huart1.Init.Parity = UART_PARITY_NONE;
  huart1.Init.Mode = UART_MODE_TX_RX;
  huart1.Init.HwFlowCtl = UART_HWCONTROL_NONE;
  huart1.Init.OverSampling = UART_OVERSAMPLING_16;
  huart1.Init.OneBitSampling = UART_ONE_BIT_SAMPLE_DISABLE;
  huart1.Init.Prescaler = UART_PRESCALER_DIV1;
  huart1.Init.FIFOMode = UART_FIFOMODE_DISABLE;
  huart1.Init.TXFIFOThreshold = UART_TXFIFO_THRESHOLD_1_8;
  huart1.Init.RXFIFOThreshold = UART_RXFIFO_THRESHOLD_1_8;
  huart1.AdvancedInit.AdvFeatureInit = UART_ADVFEATURE_NO_INIT;
  if (HAL_MultiProcessor_Init(&huart1, 0, UART_WAKEUPMETHOD_IDLELINE) != HAL_OK)
  {
    Error_Handler();
  }

}

static void MX_USART6_UART_Init(void)
{

  huart6.Instance = USART6;
  huart6.Init.BaudRate = 115200;
  huart6.Init.WordLength = UART_WORDLENGTH_8B;
  huart6.Init.StopBits = UART_STOPBITS_1;
  huart6.Init.Parity = UART_PARITY_NONE;
  huart6.Init.Mode = UART_MODE_TX_RX;
  huart6.Init.HwFlowCtl = UART_HWCONTROL_NONE;
  huart6.Init.OverSampling = UART_OVERSAMPLING_16;
  huart6.Init.OneBitSampling = UART_ONE_BIT_SAMPLE_DISABLE;
  huart6.Init.Prescaler = UART_PRESCALER_DIV1;
  huart6.Init.FIFOMode = UART_FIFOMODE_DISABLE;
  huart6.Init.TXFIFOThreshold = UART_TXFIFO_THRESHOLD_1_8;
  huart6.Init.RXFIFOThreshold = UART_RXFIFO_THRESHOLD_1_8;
  huart6.AdvancedInit.AdvFeatureInit = UART_ADVFEATURE_NO_INIT;
  if (HAL_UART_Init(&huart6) != HAL_OK)
  {
    Error_Handler();
  }

}

static void MX_USB_OTG_HS_USB_Init(void)
{

}

/* FMC initialization function */
static void MX_FMC_Init(void)
{
  FMC_SDRAM_TimingTypeDef SdramTiming;

  /** Perform the SDRAM1 memory initialization sequence
  */
  hsdram1.Instance = FMC_SDRAM_DEVICE;
  /* hsdram1.Init */
  hsdram1.Init.SDBank = FMC_SDRAM_BANK1;
  hsdram1.Init.ColumnBitsNumber = FMC_SDRAM_COLUMN_BITS_NUM_9;
  hsdram1.Init.RowBitsNumber = FMC_SDRAM_ROW_BITS_NUM_13;
  hsdram1.Init.MemoryDataWidth = FMC_SDRAM_MEM_BUS_WIDTH_16;
  hsdram1.Init.InternalBankNumber = FMC_SDRAM_INTERN_BANKS_NUM_4;
  hsdram1.Init.CASLatency = FMC_SDRAM_CAS_LATENCY_2;
  hsdram1.Init.WriteProtection = FMC_SDRAM_WRITE_PROTECTION_DISABLE;
  hsdram1.Init.SDClockPeriod = FMC_SDRAM_CLOCK_PERIOD_2;
  hsdram1.Init.ReadBurst = FMC_SDRAM_RBURST_ENABLE;
  hsdram1.Init.ReadPipeDelay = FMC_SDRAM_RPIPE_DELAY_0;
  /* SdramTiming */
  SdramTiming.LoadToActiveDelay = 2;
  SdramTiming.ExitSelfRefreshDelay = 8;
  SdramTiming.SelfRefreshTime = 6;
  SdramTiming.RowCycleDelay = 6;
  SdramTiming.WriteRecoveryTime = 4;
  SdramTiming.RPDelay = 2;
  SdramTiming.RCDDelay = 2;

  if (HAL_SDRAM_Init(&hsdram1, &SdramTiming) != HAL_OK)
  {
    Error_Handler( );
  }

}

static void MX_GPIO_Init(void)
{
  GPIO_InitTypeDef GPIO_InitStruct = {0};

  /* GPIO Ports Clock Enable */
  __HAL_RCC_GPIOE_CLK_ENABLE();
  __HAL_RCC_GPIOC_CLK_ENABLE();
  __HAL_RCC_GPIOF_CLK_ENABLE();
  __HAL_RCC_GPIOH_CLK_ENABLE();
  __HAL_RCC_GPIOA_CLK_ENABLE();
  __HAL_RCC_GPIOB_CLK_ENABLE();
  __HAL_RCC_GPIOG_CLK_ENABLE();
  __HAL_RCC_GPIOD_CLK_ENABLE();

  /*Configure GPIO pin Output Level */
  HAL_GPIO_WritePin(F030_RST_GPIO_Port, F030_RST_Pin, GPIO_PIN_SET);

  /*Configure GPIO pin Output Level */
  HAL_GPIO_WritePin(F303_RST_GPIO_Port, F303_RST_Pin, GPIO_PIN_SET);

  /*Configure GPIO pin Output Level */
  HAL_GPIO_WritePin(GPIOA, F303_SCS_Pin|F030_SCS_Pin, GPIO_PIN_SET);

  /*Configure GPIO pin Output Level */
  HAL_GPIO_WritePin(SYS_LED_GPIO_Port, SYS_LED_Pin, GPIO_PIN_RESET);

  /*Configure GPIO pin : F030_RST_Pin */
  GPIO_InitStruct.Pin = F030_RST_Pin;
  GPIO_InitStruct.Mode = GPIO_MODE_OUTPUT_PP;
  GPIO_InitStruct.Pull = GPIO_NOPULL;
  GPIO_InitStruct.Speed = GPIO_SPEED_FREQ_VERY_HIGH;
  HAL_GPIO_Init(F030_RST_GPIO_Port, &GPIO_InitStruct);

  /*Configure GPIO pin : EXT_RST_Pin */
  GPIO_InitStruct.Pin = EXT_RST_Pin;
  GPIO_InitStruct.Mode = GPIO_MODE_IT_RISING_FALLING;
  GPIO_InitStruct.Pull = GPIO_PULLUP;
  HAL_GPIO_Init(EXT_RST_GPIO_Port, &GPIO_InitStruct);

  /*Configure GPIO pin : F303_RST_Pin */
  GPIO_InitStruct.Pin = F303_RST_Pin;
  GPIO_InitStruct.Mode = GPIO_MODE_OUTPUT_PP;
  GPIO_InitStruct.Pull = GPIO_NOPULL;
  GPIO_InitStruct.Speed = GPIO_SPEED_FREQ_VERY_HIGH;
  HAL_GPIO_Init(F303_RST_GPIO_Port, &GPIO_InitStruct);

  /*Configure GPIO pins : F303_SCS_Pin F030_SCS_Pin */
  GPIO_InitStruct.Pin = F303_SCS_Pin|F030_SCS_Pin;
  GPIO_InitStruct.Mode = GPIO_MODE_OUTPUT_PP;
  GPIO_InitStruct.Pull = GPIO_NOPULL;
  GPIO_InitStruct.Speed = GPIO_SPEED_FREQ_VERY_HIGH;
  HAL_GPIO_Init(GPIOA, &GPIO_InitStruct);

  /*Configure GPIO pins : PB12 PB14 PB15 */
  GPIO_InitStruct.Pin = GPIO_PIN_12|GPIO_PIN_14|GPIO_PIN_15;
  GPIO_InitStruct.Mode = GPIO_MODE_AF_PP;
  GPIO_InitStruct.Pull = GPIO_NOPULL;
  GPIO_InitStruct.Speed = GPIO_SPEED_FREQ_LOW;
  GPIO_InitStruct.Alternate = GPIO_AF12_OTG2_FS;
  HAL_GPIO_Init(GPIOB, &GPIO_InitStruct);

  /*Configure GPIO pin : SDMMC1_INS_Pin */
  GPIO_InitStruct.Pin = SDMMC1_INS_Pin;
  GPIO_InitStruct.Mode = GPIO_MODE_INPUT;
  GPIO_InitStruct.Pull = GPIO_PULLUP;
  HAL_GPIO_Init(SDMMC1_INS_GPIO_Port, &GPIO_InitStruct);

  /*Configure GPIO pins : F030_INT_Pin F303_INT_Pin */
  GPIO_InitStruct.Pin = F030_INT_Pin|F303_INT_Pin;
  GPIO_InitStruct.Mode = GPIO_MODE_IT_RISING;
  GPIO_InitStruct.Pull = GPIO_NOPULL;
  HAL_GPIO_Init(GPIOD, &GPIO_InitStruct);

  /*Configure GPIO pin : SYS_LED_Pin */
  GPIO_InitStruct.Pin = SYS_LED_Pin;
  GPIO_InitStruct.Mode = GPIO_MODE_OUTPUT_PP;
  GPIO_InitStruct.Pull = GPIO_NOPULL;
  GPIO_InitStruct.Speed = GPIO_SPEED_FREQ_VERY_HIGH;
  HAL_GPIO_Init(SYS_LED_GPIO_Port, &GPIO_InitStruct);

  /* EXTI interrupt init*/
  HAL_NVIC_SetPriority(EXTI15_10_IRQn, 3, 0);
  HAL_NVIC_EnableIRQ(EXTI15_10_IRQn);

}

void Error_Handler(void)
{
}

/************************ (C) COPYRIGHT STMicroelectronics *****END OF FILE****/
